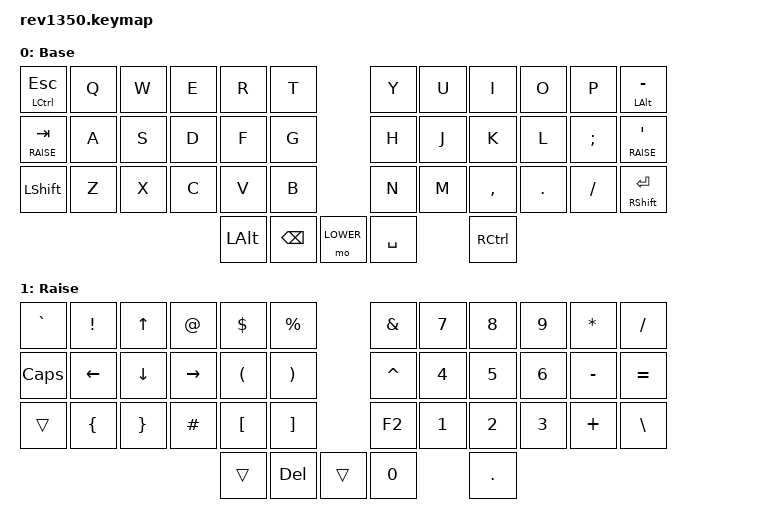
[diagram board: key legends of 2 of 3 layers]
/*
 * Copyright (c) 2020 The ZMK Contributors
 *
 * SPDX-License-Identifier: MIT
 */

#include <behaviors.dtsi>
#include <dt-bindings/zmk/keys.h>
#include <dt-bindings/zmk/rgb.h>
#include <dt-bindings/zmk/bt.h>
#include <dt-bindings/zmk/ext_power.h>
#include <dt-bindings/zmk/outputs.h>

#define BASE    0
#define RAISE   1
#define LOWER   2

&mt {
    retro-tap;
    flavor = "tap-preferred";
};
&lt {
    retro-tap;
    flavor = "tap-preferred";
};





/ {
    behaviors {
        mthp: hold_preferred_tap {
                        compatible = "zmk,behavior-hold-tap";
                        label = "HOLD_PREFERRED_TAP";            
                        #binding-cells = <2>;
                        tapping-term-ms = <125>;                  
                        flavor = "hold-preferred";      
                        bindings = <&kp>, <&kp>;
        };
    };

        keymap {
                compatible = "zmk,keymap";

                base_layer {
                        label = "Base";

                       bindings = <
   &mt LCTRL ESC   &kp Q  &kp W  &kp E  &kp R  &kp T              &kp Y &kp U  &kp I     &kp O   &kp P    &mt LALT MINUS
   &lt RAISE TAB   &kp A  &kp S  &kp D  &kp F  &kp G              &kp H &kp J  &kp K     &kp L   &kp SEMI &lt RAISE SQT
   &kp LSHFT       &kp Z  &kp X  &kp C  &kp V  &kp B              &kp N &kp M  &kp COMMA &kp DOT &kp FSLH &mthp RSHFT ENTER
                                     &kp LALT  &kp BSPC &mo LOWER &kp SPACE  &kp RCTRL 
                        >;
                };

                raise_layer {
                        label = "Raise";

                        bindings = <
   &kp GRAVE &kp EXCL   &kp UP    &kp AT     &kp DLLR &kp PRCNT           &kp AMPS  &kp N7  &kp N8 &kp N9  &kp STAR  &kp FSLH
   &kp CAPS  &kp LEFT   &kp DOWN  &kp RIGHT  &kp LPAR &kp RPAR            &kp CARET &kp N4  &kp N5 &kp N6  &kp MINUS &kp EQUAL
   &trans    &kp LBRC   &kp RBRC  &kp POUND  &kp LBKT &kp RBKT            &kp F2    &kp N1  &kp N2 &kp N3  &kp PLUS  &kp BSLH
                                            &trans    &kp DEL    &trans   &kp N0    &kp DOT
                        >;
                };

                lower_layer {
                        label = "Lower";

                        bindings = <
   &reset      &kp LG(TAB)        &bt BT_SEL 0   &bt BT_SEL 1   &bt BT_SEL 2  &kp LA(F4)        &kp PSCRN   &kp C_VOL_UP  &kp HOME     &kp PG_UP    &kp F11   &reset
   &bootloader &kp LC(N1)         &kp LC(N2)     &kp LC(N3)     &kp LC(N4)    &kp LC(N9)        &trans      &kp C_VOL_DN  &kp END      &kp PG_DN    &trans    &bootloader
   &trans      &ext_power EP_TOG  &bt BT_CLR     &kp CAPS       &trans        &kp LG(DOT)       &trans      &kp C_MUTE    &out OUT_BLE &out OUT_USB &trans
                                                                           &trans  &trans &trans &trans  &trans
                        >;
                };

        };
};
